# nrf54ls05a_application register map
Vendor: Nordic Semiconductor; Series: nrf54l; File version: 1
CPU: CM33 r0p4, little endian, MPU, no FPU, 3 interrupt priority bits, 270 interrupts
Registers are 32-bit, read-write, reset 0x0 unless marked. A register's access mark holds for its fields unless they carry their own. Offsets are from the block's base; [hi:lo] are bit positions; lines under a group give offsets from that group; {n}, {i} and the like mark numbered series; 'fields as' and 'values as' point back to an identical list.

## GLOBAL_CRACENCORE — CRACENCORE
Base 0x40059000; alternate view of GLOBAL_CRACEN
0x500 RNGCONTROL group — Unspecified
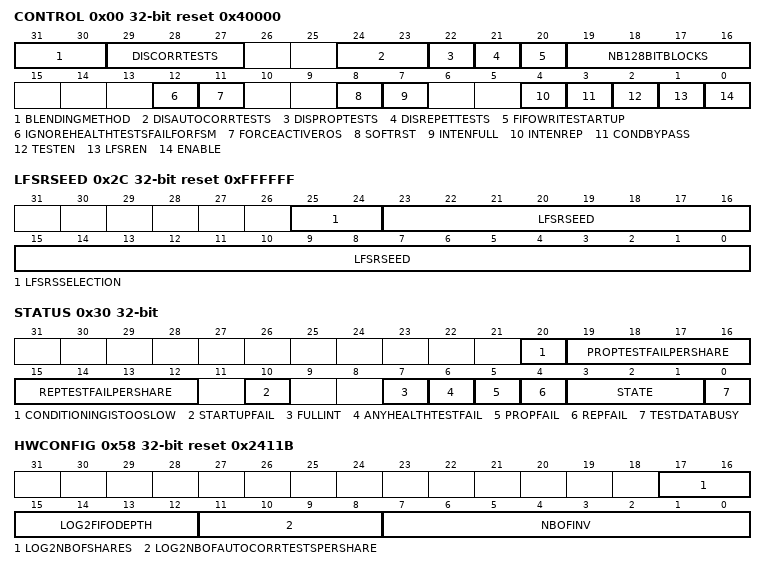
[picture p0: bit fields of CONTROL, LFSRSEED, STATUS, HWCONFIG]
  0x00 CONTROL reset 0x40000
    [31:30] BLENDINGMETHOD — Select blending method
      0=CONCATENATION; 1=XORLEVEL1; 2=XORLEVEL2; 3=VONNEUMANN (VON-NEUMANN debiasing)
    [29:27] DISCORRTESTS — Disable specific delay(s) check in correlation test - different ROs:
    [24:23] DISAUTOCORRTESTS — Disable specific delay(s) check in auto-correlation test - same RO:
    [22] DISPROPTESTS — All proportion tests (each share) are disabled via this single bit.
    [21] DISREPETTESTS — All repetition tests (each share) are disabled via this single bit.
    [20] FIFOWRITESTARTUP — Enable write of the samples in the FIFO during start-up.
      1=Recommended (Current recommended value. May change in future documentation releases without a hardware change.)
    [19:16] NB128BITBLOCKS — Number of 128 bit blocks used in conditioning (AES-CBC-MAC) post-processing.
      4=Recommended (Current recommended value. May change in future documentation releases without a hardware change.)
    [12] IGNOREHEALTHTESTSFAILFORFSM — Results of the health tests during start-up and online test do not affect the control FSM state.
    [11] FORCEACTIVEROS — Force oscillators to run when FIFO is full.
    [8] SOFTRST — Datapath content flush and control FSM
    [7] INTENFULL — Enable interrupt if FIFO is full.
    [4] INTENREP — Enable interrupt if any of the health test fails.
    [3] CONDBYPASS — Conditioning function bypass.
      0=NORMAL (the conditioning function is used (normal mode).); 1=BYPASS (the conditioning function is bypassed (to observe entropy source directly).)
    [2] TESTEN — Select input for conditioning function and continuous tests:
      0=NORMAL (Noise source (normal mode).); 1=TEST (Test data register (test mode).)
    [1] LFSREN — Select between the NDRNG with asynchronous free running oscillators (when 0) and the Pseudo-Random generator with synchronous oscillators for simulation purpose (when 1).
    [0] ENABLE wo — Start the NDRNG. Self-clearing bit.
  0x04 FIFOLEVEL
    [31:0] FIFOLEVEL — Number of 32 bits words of random values available in the FIFO.
  0x08 FIFOTHRESHOLD reset 0x3
    [2:0] FIFOTHRESHOLD — FIFO level threshold below which the module leaves the idle state to refill the FIFO. Expressed in number of 128bit blocks.
  0x0C FIFODEPTH reset 0x10
    [31:0] FIFODEPTH ro — Maximum number of 32 bits words that can be stored in the FIFO.
  {0x10+4j} KEY[{j}] (j=0..3) — Description collection: Key register.
    [31:0] KEY
  0x20 TESTDATA
    [31:0] TESTDATA wo
  0x24 REPEATTHRESHOLD reset 0x4 — Repetition test cut-off register.
    [5:0] REPEATTHRESHOLD — Repetition Test cut-off value.
      21=Recommended (Current recommended value. May change in future documentation releases without a hardware change.)
  0x28 PROPTESTCUTOFF reset 0xD — Proportion test cut-off register.
    [8:0] PROPTESTCUTOFF — Proportion test cut-off value.
      0x137=Recommended (Current recommended value. May change in future documentation releases without a hardware change.)
  0x2C LFSRSEED reset 0xFFFFFF
    [25:24] LFSRSSELECTION wo — Share index for which initialization value should be used.
    [23:0] LFSRSEED — LFSR initialization value.
  0x30 STATUS
    [20] CONDITIONINGISTOOSLOW write-0-clears — Conditioning consumes data slower than they are provided to it.
    [19:16] PROPTESTFAILPERSHARE ro — NIST Proportion test failure per share.
    [15:12] REPTESTFAILPERSHARE ro — NIST Repetition test failure per share.
    [10] STARTUPFAIL write-0-clears — Start-up test(s) failure.
    [7] FULLINT ro — FIFO full status.
    [6] ANYHEALTHTESTFAIL write-0-clears — Any of the enabled health tests is failing.
    [5] PROPFAIL ro — NIST proportion test(s) failure.
    [4] REPFAIL ro — NIST repetition test(s) failure.
    [3:1] STATE ro — State of the control FSM:
      0=RESET; 1=STARTUP; 2=IDLERON (Idle / FIFO full); 4=FILLFIFO; 5=ERROR
    [0] TESTDATABUSY ro — High when data written to TestData register is being processed.
  0x34 WARMUPPERIOD reset 0x200 — Number of clock cycles in warm-up sequence.
    [11:0] WARMUPPERIOD
      0x200=Recommended (Current recommended value. May change in future documentation releases without a hardware change.)
  0x38 DISABLEOSC
    [31:0] DISABLEOSC — Disable oscillator rings.
      0=Recommended (Current recommended value. May change in future documentation releases without a hardware change.)
  0x44 SAMPLINGPERIOD reset 0xFFF — Number of clock cycles between sampling moments.
    [11:0] SAMPLINGPERIOD
      values as RNGCONTROL.WARMUPPERIOD.WARMUPPERIOD
  0x58 HWCONFIG reset 0x2411B — Hardware configuration register.
    [17:16] LOG2NBOFSHARES ro — Generic g_Log2NbOfShares value.
    [15:12] LOG2FIFODEPTH ro — Generic g_Log2FifoDepth value.
    [11:8] LOG2NBOFAUTOCORRTESTSPERSHARE ro — Generic g_Log2NbOfAutoCorrTestsPerShare value.
    [7:0] NBOFINV ro — Generic g_NbOfInverters value.
  0x5C COOLDOWNPERIOD — Number of clock cycles in cool-down sequence.
    [11:0] COOLDOWNPERIOD
      values as RNGCONTROL.DISABLEOSC.DISABLEOSC
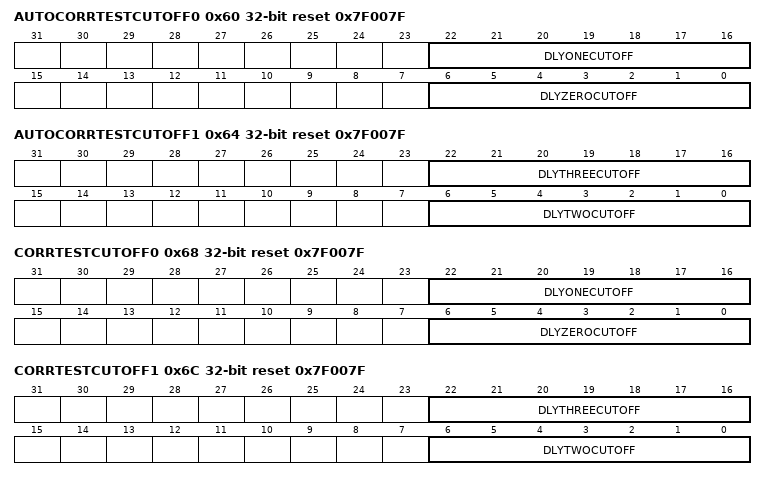
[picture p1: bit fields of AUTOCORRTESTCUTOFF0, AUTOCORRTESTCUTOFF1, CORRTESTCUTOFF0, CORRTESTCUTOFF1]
  0x60 AUTOCORRTESTCUTOFF0 reset 0x7F007F — AutoCorrTestCutoff register 0
    [22:16] DLYONECUTOFF — Auto-correlation test cut-off value for delay of +1 sample.
    [6:0] DLYZEROCUTOFF — Auto-correlation test cut-off value for delay of 0 samples.
  0x64 AUTOCORRTESTCUTOFF1 reset 0x7F007F — AutoCorrTestCutoff register 1
    [22:16] DLYTHREECUTOFF — Auto-correlation test cut-off value for delay of +3 samples.
    [6:0] DLYTWOCUTOFF — Auto-correlation test cut-off value for delay of +2 samples.
  0x68 CORRTESTCUTOFF0 reset 0x7F007F — CorrTestCutoff register 0
    [22:16] DLYONECUTOFF — Correlation test cut-off value for delay of +/-1 sample.
    [6:0] DLYZEROCUTOFF — Correlation test cut-off value for delay of 0 samples.
  0x6C CORRTESTCUTOFF1 reset 0x7F007F — CorrTestCutoff register 1
    [22:16] DLYTHREECUTOFF — Correlation test cut-off value for delay of +/- 3 samples.
    [6:0] DLYTWOCUTOFF — Correlation test cut-off value for delay of +/- 2 samples.
  0x70 AUTOCORRTESTFAILED — Auto-correlation test failing ring(s).
    [31:0] AUTOCORRTESTFAILED ro
  0x74 CORRTESTFAILED — Correlation test failing ring.
    [31:0] CORRTESTFAILED ro
  0x7C HWVERSION reset 0x1 — Fixed to 1 for this version.
    [31:0] HWVERSION ro
  {0x80+4j} FIFO[{j}] (j=0..31) ro — Description collection: FIFO data
    [31:0] DATA — FIFO data

## Notices in the file
Copyright (c) 2010 - 2026, Nordic Semiconductor ASA All rights reserved.
SPDX-License-Identifier: BSD-3-Clause
Redistribution and use in source and binary forms, with or without
modification, are permitted provided that the following conditions are met:
1. Redistributions of source code must retain the above copyright notice, this
list of conditions and the following disclaimer.
2. Redistributions in binary form must reproduce the above copyright
notice, this list of conditions and the following disclaimer in the
documentation and/or other materials provided with the distribution.
3. Neither the name of Nordic Semiconductor ASA nor the names of its
contributors may be used to endorse or promote products derived from this
software without specific prior written permission.
THIS SOFTWARE IS PROVIDED BY THE COPYRIGHT HOLDERS AND CONTRIBUTORS "AS IS"
AND ANY EXPRESS OR IMPLIED WARRANTIES, INCLUDING, BUT NOT LIMITED TO, THE
IMPLIED WARRANTIES OF MERCHANTABILITY, AND FITNESS FOR A PARTICULAR PURPOSE
ARE DISCLAIMED. IN NO EVENT SHALL NORDIC SEMICONDUCTOR ASA OR CONTRIBUTORS BE
LIABLE FOR ANY DIRECT, INDIRECT, INCIDENTAL, SPECIAL, EXEMPLARY, OR
CONSEQUENTIAL DAMAGES (INCLUDING, BUT NOT LIMITED TO, PROCUREMENT OF
SUBSTITUTE GOODS OR SERVICES; LOSS OF USE, DATA, OR PROFITS; OR BUSINESS
INTERRUPTION) HOWEVER CAUSED AND ON ANY THEORY OF LIABILITY, WHETHER IN
CONTRACT, STRICT LIABILITY, OR TORT (INCLUDING NEGLIGENCE OR OTHERWISE)
ARISING IN ANY WAY OUT OF THE USE OF THIS SOFTWARE, EVEN IF ADVISED OF THE
POSSIBILITY OF SUCH DAMAGE.
